AUTOSAR XML (schema 00048)
package /HuaweiMDC/PlatformApplication/SmClientApplication/Execution
  executable sm_client
    root sw component prototype sm_client: application-type=sm_client
package /HuaweiMDC/PlatformApplication/SmClientApplication/SwComponent
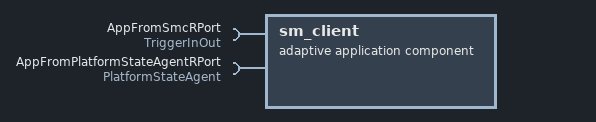
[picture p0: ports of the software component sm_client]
  adaptive application sw component type sm_client
    require port AppFromSmcRPort: required-interface=TriggerInOut
    require port AppFromPlatformStateAgentRPort: required-interface=PlatformStateAgent
